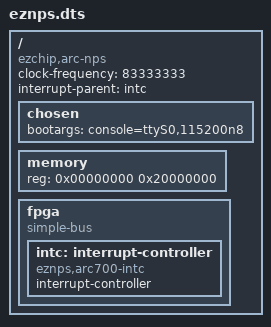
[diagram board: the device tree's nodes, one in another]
/*******************************************************************************

  ARC700 Device Tree Structure
  Copyright(c) 2012 EZchip Technologies.

  This program is free software; you can redistribute it and/or modify it
  under the terms and conditions of the GNU General Public License,
  version 2, as published by the Free Software Foundation.

  This program is distributed in the hope it will be useful, but WITHOUT
  ANY WARRANTY; without even the implied warranty of MERCHANTABILITY or
  FITNESS FOR A PARTICULAR PURPOSE.  See the GNU General Public License for
  more details.

  The full GNU General Public License is included in this distribution in
  the file called "COPYING".

*******************************************************************************/
/dts-v1/;

/include/ "skeleton.dtsi"

/ {
	compatible = "ezchip,arc-nps";
	clock-frequency = <83333333>;	/* 83.333333 MHZ */
	#address-cells = <1>;
	#size-cells = <1>;
	interrupt-parent = <&intc>;

	chosen {
		bootargs = "console=ttyS0,115200n8";
	};

	memory {
		device_type = "memory";
		reg = <0x00000000 0x20000000>;	/* 512M */
	};

	fpga {
		compatible = "simple-bus";
		#address-cells = <1>;
		#size-cells = <1>;

		/* child and parent address space 1:1 mapped */
		ranges;

		intc: interrupt-controller {
			compatible = "eznps,arc700-intc";
			interrupt-controller;
			#interrupt-cells = <1>;
		};
	};
};
